# sDMA register map
Vendor: Texas Instruments
Peripheral module from a debugger description file (folder omap4460).
Registers are 32-bit, read-write, reset values left out (the file's numbers can be read two ways) unless marked. A register's access mark holds for its fields unless they carry their own. Offsets are as the file gives them; lines under a group give offsets from that group; [hi:lo] are bit positions; {n}, {i} and the like mark numbered series; 'fields as' and 'values as' point back to an identical list; <NAME> marks a mode.

## SDMA
0x00 DMA4_REVISION ro — This register contains the DMA revision code
  [31:0] REVISION — Reserved, Write 0's for future compatibility. Read returns 0
{0x8+4i} DMA4_IRQSTATUS_Lj_{i} (i=0..3) — The interrupt status register regroups all the status of the DMA4 channels that can generate an interrupt over line Lj.
  [31:0] CH_31_0_Lj — Channel 31 Interrupt on Lj: When an interrupt is seen on the line Lj the status of a interrupting channel i is read in the bit field i.
    0=CH_31_0_Lj_0_r (Channel Interrupt Lj false); 0=CH_31_0_Lj_0_w (Channel Interrupt Lj status bit unchanged); 1=CH_31_0_Lj_1_w (Channel Interrupt Lj status bit is reset); 1=CH_31_0_Lj_1_r (Channel Interrupt Lj true (pending))
{0x18+4i} DMA4_IRQENABLE_Lj_{i} (i=0..3) — The interrupt enable register allows to mask/unmask the module internal sources of interrupt, on line Lj
  [31:0] CH_31_0_Lj_EN — Channel Interrupt on Lj mask/unmask : to Mask/Unmask a channel i interrupt on Lj the user writes 0/1 on the bit field i.
    0=Channel Interrupt Lj is masked; 1=Channel Interrupt Lj generates an interrupt when it occurs
0x28 DMA4_SYSSTATUS ro — The register provides status information about the module excluding the interrupt status information (see interrupt status register)
  [0] RESETDONE — Internal reset monitoring
    0=RESETDONE_0_r (Internal module reset is on-going); 1=RESETDONE_1_r (Reset completed)
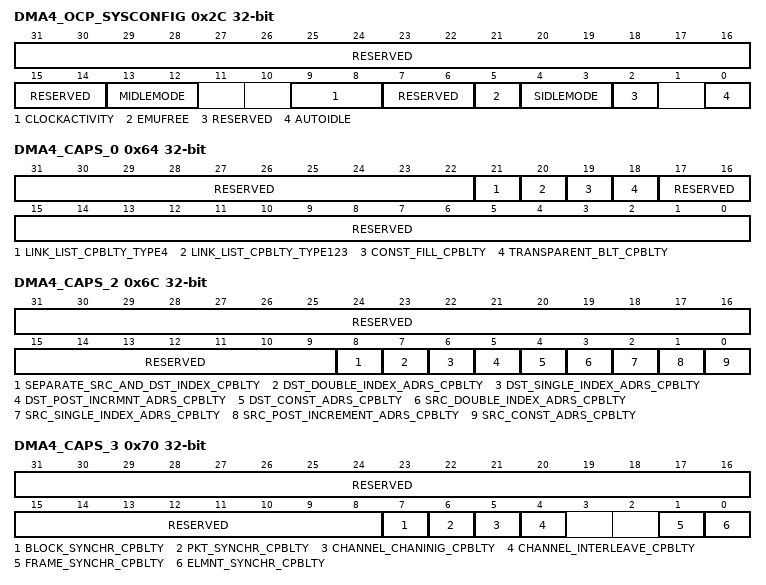
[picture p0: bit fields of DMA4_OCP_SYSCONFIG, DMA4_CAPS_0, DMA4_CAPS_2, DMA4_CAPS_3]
0x2C DMA4_OCP_SYSCONFIG access per field — DMA system configuration register
  [31:14] RESERVED rw — Write 0's for future compatibility, Reads return 0
  [13:12] MIDLEMODE rw — Read write power management, standby/wait control
    0=Force-standby: MStandby is asserted only when all the DMA channels are disabled; 1=No-Standby: MStandby is never asserted; 2=Smart-Standby: MStandby is asserted if at least one of the following two conditions is satisfied: 1. All the channels are disabled, OR 2. There is no non-synchronized channel enabled AND [if hardware synchronized channel is enabled, then no DMA request input is asserted and no requests are pending to be serviced].
  [9:8] CLOCKACTIVITY ro — Clocks activities during wake-up Bit 8: Interface clock 0x0: Interface clock can be switched-off Bit 9: Functional clock 0x0: Functional clock can be switched-off
  [7:6] RESERVED rw — Write 0's for future compatibility. Read returns 0
  [5] EMUFREE rw — Enable sensitivity to MSuspend
    0=DMA4 freezes its internal logic upon MSuspend assertion; 1=DMA4 ignores the MSuspend input
  [4:3] SIDLEMODE rw — Configuration port power management, Idle req/ack control
    0=Force-idle. An idle request is acknowledged unconditionally; 1=No-idle. An idle request is never acknowledged; 2=Smart-idle. Idle acknowledge is given by DMA4 if all of the conditions are true: 1. All the channels are disabled. 2. If hardware synchronized channel is enabled, then no DMA request input is asserted and no requests are pending to be serviced. 3. All transactions are completed on all the DMA ports. 4.No interrupts are pending to be serviced.; 3=Reserved. Do not use
  [2] RESERVED rw — Write 0's for future compatibility, Reads return 0
  [0] AUTOIDLE rw — Internal interface clock gating strategy
    0=Interface clock is free running; 1=Automatic interface clock gating strategy is applied, based on the interface activity
0x64 DMA4_CAPS_0 access per field — DMA Capabilities Register 0 LSW
  [31:22] RESERVED rw — Write 0's for future compatibility. Read returns 0
  [21] LINK_LIST_CPBLTY_TYPE4 ro — Link List capability for type4 descriptor capability
  [20] LINK_LIST_CPBLTY_TYPE123 ro — Link List capability for type123 descriptor capability
  [19] CONST_FILL_CPBLTY ro — Constant_Fill_Capability
    0=CONST_FILL_CPBLTY_0_r (No LCH supports constant fill copy); 1=CONST_FILL_CPBLTY_1_r (any LCH supports constant fill copy)
  [18] TRANSPARENT_BLT_CPBLTY ro — Transparent_BLT_Capability
    0=TRANSPARENT_BLT_CPBLTY_0_r (No LCH supports transparent BLT copy); 1=TRANSPARENT_BLT_CPBLTY_1_r (any LCH supports transparent BLT copy)
  [17:0] RESERVED rw — Write 0's for future compatibility. Read returns 0
0x6C DMA4_CAPS_2 ro — DMA Capabilities Register 2
  [31:9] RESERVED — Write 0's for future compatibility. Read returns 0
  [8] SEPARATE_SRC_AND_DST_INDEX_CPBLTY — Separate_source/destination_index_capability
    0=SEPARATE_SRC_AND_DST_INDEX_CPBLTY_0_r (Does not support separate src/dst index for 2D addressing); 1=SEPARATE_SRC_AND_DST_INDEX_CPBLTY_1_r (Supports separate src/dest index for 2D addressing)
  [7] DST_DOUBLE_INDEX_ADRS_CPBLTY — Destination_double_index_address_capability
    0=DST_DOUBLE_INDEX_ADRS_CPBLTY_0_r (Does not support double index address mode on the destination port); 1=DST_DOUBLE_INDEX_ADRS_CPBLTY_1_r (Supports double index address mode on the destination port)
  [6] DST_SINGLE_INDEX_ADRS_CPBLTY — Destination_single_index_address_capability
    0=DST_SINGLE_INDEX_ADRS_CPBLTY_0_r (Does not support single index address mode on the destination port); 1=DST_SINGLE_INDEX_ADRS_CPBLTY_1_r (Supports single index address mode on the destination port)
  [5] DST_POST_INCRMNT_ADRS_CPBLTY — Destination_post_increment_address_capability
    0=DST_POST_INCRMNT_ADRS_CPBLTY_0_r (Does not supports post-increment address mode in the destination port); 1=DST_POST_INCRMNT_ADRS_CPBLTY_1_r (Supports post-increment address mode in the destination port)
  [4] DST_CONST_ADRS_CPBLTY — Destination_constant_address_capability
    0=DST_CONST_ADRS_CPBLTY_0_r (Does not supports constant address mode in the destination port); 1=DST_CONST_ADRS_CPBLTY_1_r (Supports constant address mode in the destination port)
  [3] SRC_DOUBLE_INDEX_ADRS_CPBLTY — Source_double_index_address_capability
    0=SRC_DOUBLE_INDEX_ADRS_CPBLTY_0_r (Does not support double index address mode on the source port); 1=SRC_DOUBLE_INDEX_ADRS_CPBLTY_1_r (Supports double index address mode on the source port)
  [2] SRC_SINGLE_INDEX_ADRS_CPBLTY — Source_single_index_address_capability
    0=SRC_SINGLE_INDEX_ADRS_CPBLTY_0_r (Does not support single index address mode on the source port); 1=SRC_SINGLE_INDEX_ADRS_CPBLTY_1_r (Supports single index address mode in the source port)
  [1] SRC_POST_INCREMENT_ADRS_CPBLTY — Source_post_increment_address_capability
    0=SRC_POST_INCREMENT_ADRS_CPBLTY_0_r (Does not supports post-increment address mode in the source port); 1=SRC_POST_INCREMENT_ADRS_CPBLTY_1_r (Supports post-increment address mode in the source port)
  [0] SRC_CONST_ADRS_CPBLTY — Source_constant_address_capability
    0=SRC_CONST_ADRS_CPBLTY_0_r (Does not supports constant address mode in the source port); 1=SRC_CONST_ADRS_CPBLTY_1_r (Supports constant address mode in the source port)
0x70 DMA4_CAPS_3 ro — DMA Capabilities Register 3
  [31:8] RESERVED — Write 0's for future compatibility. Read returns 0
  [7] BLOCK_SYNCHR_CPBLTY — Block_synchronization_capability
    0=BLOCK_SYNCHR_CPBLTY_0_r (Does not support synchronization transfer on block boundary); 1=BLOCK_SYNCHR_CPBLTY_1_r (Supports synchronization transfer on block boundary)
  [6] PKT_SYNCHR_CPBLTY — Packet_synchronization_capability
    0=PKT_SYNCHR_CPBLTY_0_r (Does not support synchronization transfer on packet boundary); 1=PKT_SYNCHR_CPBLTY_1_r (Supports synchronization transfer on packet boundary)
  [5] CHANNEL_CHANINIG_CPBLTY — Channel_Chaninig_capability
    0=CHANNEL_CHANINIG_CPBLTY_0_r (Does not support Channel Chaninig capability); 1=CHANNEL_CHANINIG_CPBLTY_1_r (Supports Channel Chaninig capability)
  [4] CHANNEL_INTERLEAVE_CPBLTY — Channel_interleave_capability
    0=CHANNEL_INTERLEAVE_CPBLTY_0_r (Does not support Channel interleave capability); 1=CHANNEL_INTERLEAVE_CPBLTY_1_r (Supports Channel_interleave capability)
  [1] FRAME_SYNCHR_CPBLTY — Frame_synchronization_capability
    0=FRAME_SYNCHR_CPBLTY_0_r (Does not support synchronization transfer on Frame boundary); 1=FRAME_SYNCHR_CPBLTY_1_r (Supports synchronization transfer on Frame boundary)
  [0] ELMNT_SYNCHR_CPBLTY — Element_synchronization_capability
    0=ELMNT_SYNCHR_CPBLTY_0_r (Does not support synchronization transfer on Element boundary); 1=ELMNT_SYNCHR_CPBLTY_1_r (Supports synchronization transfer on Element boundary)
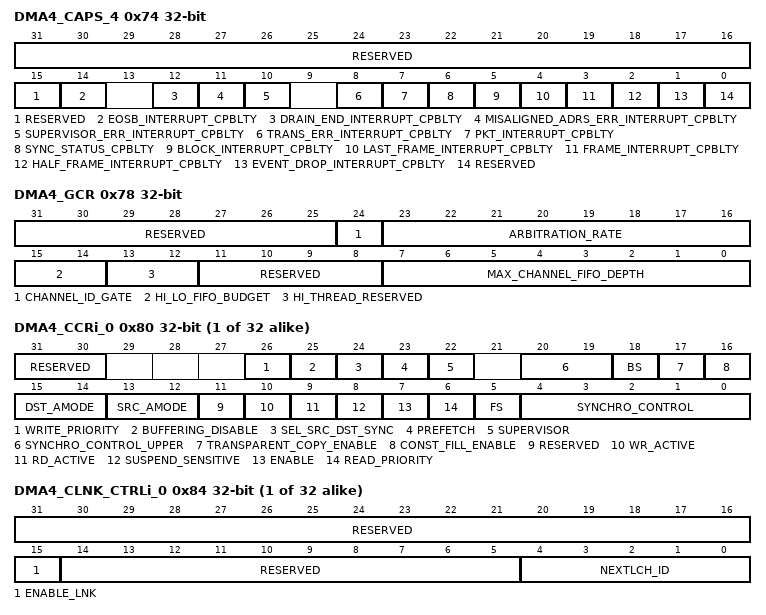
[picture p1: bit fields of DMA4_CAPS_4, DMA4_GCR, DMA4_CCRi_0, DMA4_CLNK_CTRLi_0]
0x74 DMA4_CAPS_4 access per field — DMA Capabilities Register 4
  [31:15] RESERVED rw — Write 0's for future compatibility. Read returns 0.
  [14] EOSB_INTERRUPT_CPBLTY ro — End of Super Block detection capability.
  [12] DRAIN_END_INTERRUPT_CPBLTY ro — Drain End detection capability.
  [11] MISALIGNED_ADRS_ERR_INTERRUPT_CPBLTY ro — Misaligned error detection capability.
  [10] SUPERVISOR_ERR_INTERRUPT_CPBLTY ro — Supervisor error detection capability.
  [8] TRANS_ERR_INTERRUPT_CPBLTY ro — Transaction error detection capability.
  [7] PKT_INTERRUPT_CPBLTY ro — End of Packet detection capability.
    0=PKT_INTERRUPT_CPBLTY_0_r (Does not support end of packet interrupt generation capability); 1=PKT_INTERRUPT_CPBLTY_1_r (Supports end of packet interrupt generation capability)
  [6] SYNC_STATUS_CPBLTY ro — Sync_status_capability
    0=SYNC_STATUS_CPBLTY_0_r (Does not support synchronized transfer status bit generation); 1=SYNC_STATUS_CPBLTY_1_r (Supports synchronized transfer status bit generation)
  [5] BLOCK_INTERRUPT_CPBLTY ro — End of block detection capability.
    0=BLOCK_INTERRUPT_CPBLTY_0_r (Does not support end of block interrupt generation capability); 1=BLOCK_INTERRUPT_CPBLTY_1_r (Supports end of block interrupt generation capability)
  [4] LAST_FRAME_INTERRUPT_CPBLTY ro — Start of last frame detection capability.
    0=LAST_FRAME_INTERRUPT_CPBLTY_0_r (Does not support last frame interrupt generation capability); 1=LAST_FRAME_INTERRUPT_CPBLTY_1_r (Supports last frame interrupt generation capability)
  [3] FRAME_INTERRUPT_CPBLTY ro — End of frame detection capability.
    0=FRAME_INTERRUPT_CPBLTY_0_r (Does not support end of frame interrupt generation capability); 1=FRAME_INTERRUPT_CPBLTY_1_r (Supports end of frame interrupt generation capability)
  [2] HALF_FRAME_INTERRUPT_CPBLTY ro — Detection capability of the half of frame end.
    0=HALF_FRAME_INTERRUPT_CPBLTY_0_r (Does not support half of frame interrupt generation capability); 1=HALF_FRAME_INTERRUPT_CPBLTY_1_r (Supports half of frame interrupt generation capability)
  [1] EVENT_DROP_INTERRUPT_CPBLTY ro — Request collision detection capability.
    0=EVENT_DROP_INTERRUPT_CPBLTY_0_r (Does not support event drop interrupt generation capability); 1=EVENT_DROP_INTERRUPT_CPBLTY_1_r (Supports event drop interrupt generation capability)
  [0] RESERVED rw — Write 0's for future compatibility. Read returns 0.
0x78 DMA4_GCR
  [31:25] RESERVED — Write 0's for future compatibility. Read returns 0.
  [24] CHANNEL_ID_GATE — Gates the Channel ID bus monitoring on both Read and Write ports 0x0: Gates the Channel ID qualifiers on both Read and Write Ports 0x1: Does not gate the Channel ID qualifiers on both Read and Write Ports
  [23:16] ARBITRATION_RATE — Arbitration switching rate between prioritized and regular channel queues
  [15:14] HI_LO_FIFO_BUDGET — Allow to have a separate Global FIFO budget for high and low priority channels. For Hi priority Channel: (Per_channel_Maximum FIFO depth + 1) x Number of active High priority Channel &lt;= High Budget FIFO For Low priority channel: (Per_channel_Maximum FIFO depth + 1) x Number of active Low priority Channel &lt;= Low Budget FIFO
    0=no fixed budget for neither higher nor lower priority channel; 1=75% of FIFO for low priority and 25% for high priority channels; 2=25% of FIFO for low priority and 75% for high priority channels; 3=50% of FIFO for low priority and 50% for high priority channels
  [13:12] HI_THREAD_RESERVED — Allow thread reservation for high priority channel on both read and write ports.
    0=No ThreadID is reserved on the Read Port for high priority channels. No ThreadID is reserved on the Write Port for high priority channels.; 1=Read Port ThreadID 0 is reserved for high priority channels. Write Port ThreadID 0 is reserved for high priority channels.; 2=Read port ThreadID 0 and ThreadID 1 are reserved for high priority channels. Write Port ThreadID 0 is reserved for high priority channels.; 3=Read PortThreadID 0, ThreadID 1 and ThreadID 2 are reserved for high priority channels. Write Port ThreadID 0 is reserved for high priority channels.
  [11:8] RESERVED — Write 0's for future compatibility. Read returns 0.
  [7:0] MAX_CHANNEL_FIFO_DEPTH — Maximum FIFO depth allocated to one logical channel. Maximum FIFO depth can not be 0x0. It should be at least 0x1 or greater. Note that If channel limit is less than destination burst size enough data will not be accumulated in the data FIFO and it will never be sent out on the WR port. The burst size should be less than the FIFO limit specified in this bit field.
{0x80+0x60*i} DMA4_CCRi_{i} access per field (i=0..31) — Channel Control Register
  [31:30] RESERVED rw — Write 0's for future compatibility. Read returns 0.
  [26] WRITE_PRIORITY rw — Channel priority on the Write side
    0=Channel has low priority on the write side during the arbitration process; 1=Channel has high priority on write sided during the arbitration process
  [25] BUFFERING_DISABLE rw — This bit allows to disable the default buffering functionality when transfer is source synchronized.
    0=Buffering is enabled across element/packet when source is synchronized to element, packet, frame or blocks; 1=Buffering is disabled across element/packet when source is synchronized to element, packet, frame or blocks
  [24] SEL_SRC_DST_SYNC rw — Specifies that element, packet, frame or block transfer (depending on CCR.bs and CCR.fs) is triggered by the source or the destination on the DMA request
    0=Transfer is triggered by the destination. If synch on packet the packet element number is specified in the CDFI register.; 1=Transfer is triggered by the source. If synchronized on packet the packet element number is specified in the CSFI register.
  [23] PREFETCH rw — Enables the prefetch mode
    0=Prefetch mode is disabled. When Sel_Src_Dst_Sync=1 transfers are buffered and pipelined between DMA requests.; 1=Prefetch mode is enabled. Prefetch mode is active only when destination is synchronized. It is software user responsibility not to have at the same time Prefetch=1 when Sel_Src_Dst_Sync=1. This mode is not supported.
  [22] SUPERVISOR rw — Enables the supervisor mode
    0=Supervisor mode is disabled; 1=Supervisor mode is enabled
  [20:19] SYNCHRO_CONTROL_UPPER rw — Channel Synchronization control upper (used in conjunction with the 5 bits of synchro channelDMA4_CCRi[4:0]) Used in conjunction, as 2 MSB, with the 5 bits of the synchro channel bit field.
  [18] BS rw — Block synchronization This bit used in conjunction with the fs to see how the DMA request is serviced in a synchronized transfer.
  [17] TRANSPARENT_COPY_ENABLE rw
    0=Transparent copy mode is disabled; 1=Transparent copy mode is enabled
  [16] CONST_FILL_ENABLE rw — Constant fill enable
    0=Constant fill mode is disabled; 1=Constant fill mode is enabled
  [15:14] DST_AMODE rw — Selects the addressing mode on the Write Port of a channel.
    0=Constant address mode; 1=Post-incremented address mode; 2=Single index address mode; 3=Double index address mode
  [13:12] SRC_AMODE rw — Selects the addressing mode on the Read Port of a channel.
    values as DST_AMODE
  [11] RESERVED rw — Write 0s for future compatibility. Read returns 0.
  [10] WR_ACTIVE ro — Indicates if the channel write context is active or not
    0=WR_ACTIVE_0_r (Channel is not active on the write port.); 1=WR_ACTIVE_1_r (Channel is currently active on the write port.)
  [9] RD_ACTIVE ro — Indicates if the channel read context is active or not
    0=RD_ACTIVE_0_r (Channel is not active on the read port.); 1=RD_ACTIVE_1_r (Channel is currently active on the read port.)
  [8] SUSPEND_SENSITIVE rw — Logical channel suspend enable bit
    0=The channel ignores the MSuspend even if EMUFree is set to 0; 1=If EMUFree is set to 0 and MSuspend comes in then all current OCP services (single transaction or burst transaction as specified in the corresponding CSDP register) have to be completed before stopping processing any more transactions
  [7] ENABLE rw — Logical channel enable. It is SW responsibility to clear the CSR register and the IRQSTATUS bit for the different interrupt lines before enabling the channel.
    0=The logical channel is disabled; 1=The logical channel is enabled
  [6] READ_PRIORITY rw — Channel priority on the read side
    0=Channel has low priority on the read side during the arbitration process; 1=Channel has high priority on read sided during the arbitration process
  [5] FS rw — Frame synchronization This bit used in conjunction with the BS to see how the DMA request is serviced in a synchronized transfer FS = 0 and BS = 0: An element is transferred once a DMA request is made. FS = 0 and BS = 1: An entire block is transferred once a DMA request is made. FS = 1 and BS = 0: An entire frame is transferred once a DMA request is made. FS = 1 and BS = 1: A packet is transferred once a DMA request is made. All these different transfers can be interleaved on the port with other DMA requests.
  [4:0] SYNCHRO_CONTROL rw — Channel synchronization control This bit field used in conjunction with the second_level_ synchro_control_upper (as 2 MSB) 0000000 : Is reserved for non synchronized LCH transfer xxxxxxx (from 1 to 127)There are 127 possible DMA request to assign to any LCH. The channel synchronization control registers are 1-based. For example, to enable the S_DMA_1 request, DMA4_CCR[4:0] SYNCHRO_CONTROL must be set to 0x2 (DMA request number + 1).
{0x84+0x60*i} DMA4_CLNK_CTRLi_{i} (i=0..31) — Channel Link Control Register
  [31:16] RESERVED — Write 0's for future compatibility. Read returns 0.
  [15] ENABLE_LNK — Enables or disable the channel linking.
    0=Channel linking mode is disabled When set on the fly to 0 the current channel will complete the transfer and stops the chain linking; 1=Channel linking mode is enabled. The logical channel defined in the NextLCH_ID is enabled at the end of the current transfer
  [14:5] RESERVED — Write 0's for future compatibility. Read returns 0.
  [4:0] NEXTLCH_ID — Defines the NextLCh_ID, which is used to build logical channel chaining queue.
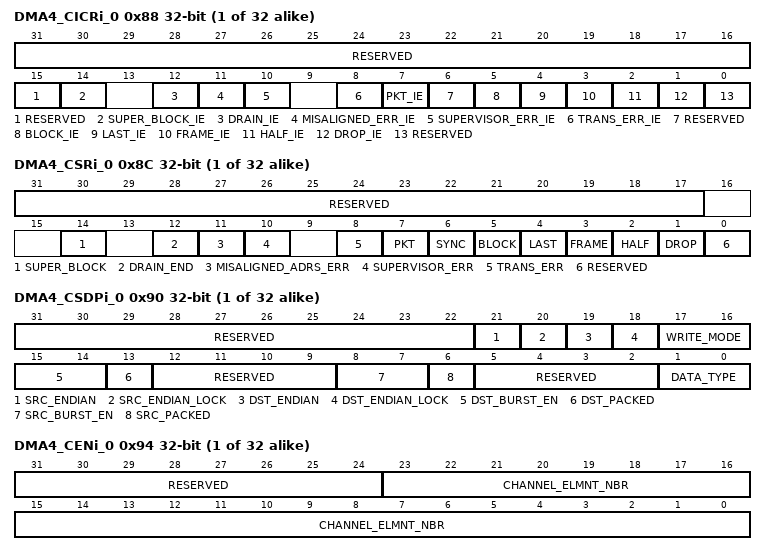
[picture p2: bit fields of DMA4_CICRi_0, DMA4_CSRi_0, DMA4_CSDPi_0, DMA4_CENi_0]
{0x88+0x60*i} DMA4_CICRi_{i} (i=0..31) — Channel Interrupt Control Register
  [31:15] RESERVED — Write 0's for future compatibility. Read returns 0.
  [14] SUPER_BLOCK_IE — Enables the end of super block interrupt
  [12] DRAIN_IE — Enables the end of draining interrupt
  [11] MISALIGNED_ERR_IE — Enables the address misaligned error event interrupt
    0=Disables the misaligned address error event interrupt; 1=Enables the misaligned address error event interrupt
  [10] SUPERVISOR_ERR_IE — Enables the supervisor transaction error event interrupt
    0=Disables the supervisor transaction error event interrupt; 1=Enables the supervisor transaction error event interrupt
  [8] TRANS_ERR_IE — Enables the transaction error event interrupt
    0=Disables the transaction error event interrupt; 1=Enables the transaction error event interrupt
  [7] PKT_IE — Enables the end of Packet interrupt
    0=Disables the end of Packet transfer interrupt; 1=Enables the end of Packet transfer interrupt
  [6] RESERVED — Write 0's for future compatibility. Read returns 0.
  [5] BLOCK_IE — Enables the end of block interrupt
    0=Disables the end of block interrupt; 1=Disables the end of block interrupt
  [4] LAST_IE — Last frame interrupt enable (start of last frame)
    0=Disables the last frame interrupt; 1=Enables the last frame interrupt
  [3] FRAME_IE — Frame interrupt enable (end of frame)
    0=Disables the end of frame interrupt; 1=Enables the end of frame interrupt
  [2] HALF_IE — Enables or disables the half frame interrupt.
    0=Disables the half frame interrupt; 1=Enables the half frame interrupt
  [1] DROP_IE — Synchronization event drop interrupt enable (request collision)
    0=Disables the event drop interrupt; 1=Enables the event drop interrupt
  [0] RESERVED — Write 0's for future compatibility. Read returns 0.
{0x8C+0x60*i} DMA4_CSRi_{i} (i=0..31) — Channel Status Register
  [31:17] RESERVED — Write 0's for future compatibility. Read returns 0.
  [14] SUPER_BLOCK — End of Super block event
  [12] DRAIN_END — End of channel draining
  [11] MISALIGNED_ADRS_ERR — Misaligned address error event
    0=MISALIGNED_ADRS_ERR_0_r (No address error); 0=MISALIGNED_ADRS_ERR_0_w (Status bit unchanged); 1=MISALIGNED_ADRS_ERR_1_w (Status bit is reset); 1=MISALIGNED_ADRS_ERR_1_r (An address error has been occurred)
  [10] SUPERVISOR_ERR — Supervisor transaction error event
    0=SUPERVISOR_ERR_0_r (No supervisor transaction error); 0=SUPERVISOR_ERR_0_w (Status bit unchanged); 1=SUPERVISOR_ERR_1_w (Status bit is reset); 1=SUPERVISOR_ERR_1_r (A supervisor transaction error has been occurred)
  [8] TRANS_ERR — Transaction error event
    0=TRANS_ERR_0_r (No transaction error); 0=TRANS_ERR_0_w (Status bit unchanged); 1=TRANS_ERR_1_w (Status bit is reset); 1=TRANS_ERR_1_r (A transaction error has been occurred)
  [7] PKT — End of Packet transfer
    0=PKT_0_r (The current packet transfer has not been finished); 0=PKT_0_w (Status bit unchanged); 1=PKT_1_w (Status bit is reset); 1=PKT_1_r (The current packet has been transferred)
  [6] SYNC — Synchronization status of a channel.
    0=SYNC_0_r (Logical channel is not scheduled or servicing a non synchronized DMA request.); 0=SYNC_0_w (Status bit unchanged); 1=SYNC_1_w (Status bit is reset); 1=SYNC_1_r (Logical channel is servicing a synchronized DMA request)
  [5] BLOCK — End of block event
    0=BLOCK_0_r (The current block transfer has not been finished); 0=BLOCK_0_w (Status bit unchanged); 1=BLOCK_1_w (Status bit is reset); 1=BLOCK_1_r (The current block has been transferred)
  [4] LAST — Last frame (start of last frame)
    0=LAST_0_r (The start of the last frame to transfer is not reached); 0=LAST_0_w (Status bit unchanged); 1=LAST_1_w (Status bit is reset); 1=LAST_1_r (The start of the last frame to transfer is reached)
  [3] FRAME — End of frame event
    0=FRAME_0_r (The end of current transferred frame is not reached); 0=FRAME_0_w (Status bit unchanged); 1=FRAME_1_w (Status bit is reset); 1=FRAME_1_r (The end of current transferred frame is reached)
  [2] HALF — Half of frame event.
    0=HALF_0_r (The half of current transferred frame is not reached); 0=HALF_0_w (Status bit unchanged); 1=HALF_1_w (Status bit is reset); 1=HALF_1_r (The half of current transferred frame is reached)
  [1] DROP — Synchronization event drop occured during the transfer
    0=DROP_0_r (No synchronization collision); 0=DROP_0_w (Status bit unchanged); 1=DROP_1_w (Status bit is reset); 1=DROP_1_r (A synchronization collision has been occurred)
  [0] RESERVED — Write 0's for future compatibility. Read returns 0.
{0x90+0x60*i} DMA4_CSDPi_{i} (i=0..31) — Channel Source Destination Parameters
  [31:22] RESERVED — Write 0's for future compatibility. Read returns 0.
  [21] SRC_ENDIAN — Channel source endianness control
    0=Source has Little Endian type; 1=Source has Big Endian type
  [20] SRC_ENDIAN_LOCK — Endianness Lock
    0=Endianness adapt; 1=Endianness lock
  [19] DST_ENDIAN — Channel Destination endianness control
    0=Destination has Little Endian type; 1=Destination has Big Endian type
  [18] DST_ENDIAN_LOCK — Endianness Lock
    0=Endianness adapt; 1=Endianness lock
  [17:16] WRITE_MODE — Used to enable writing mode without posting or with posting
    0=Write None Posted (WRNP); 1=Write (Posted); 2=All transaction are mapped on the Write command as posted except for the last transaction in the transfer mapped on a Write None Posted; 3=Undefined
  [15:14] DST_BURST_EN — Used to enable bursting on the Write Port. Smaller burst size than the programmed burst size is also allowed
    0=single access; 1=16 bytes or 4x32-bit / 2x64-bit burst access; 2=32 bytes or 8x32-bit / 4x64-bit burst access; 3=64 bytes or 16x32-bit / 8x64-bit burst access
  [13] DST_PACKED — Destination receives packed data.
    0=The destination target is non packed; 1=The destination target is packed
  [12:9] RESERVED — Write the reset value. Read returns reset value
  [8:7] SRC_BURST_EN — Used to enable bursting on the Read Port. Smaller burst size than the programmed burst size is also allowed
    values as DST_BURST_EN
  [6] SRC_PACKED — Source provides packed data.
    0=The source target is non packed; 1=The source target is packed
  [5:2] RESERVED — Write the reset value. Read returns reset value
  [1:0] DATA_TYPE — Defines the type of the data moved in the channel.
    0=8 bits scalar; 1=16 bits scalar; 2=32 bits scalar
{0x94+0x60*i} DMA4_CENi_{i} (i=0..31) — Channel Element Number
  [31:24] RESERVED — Write 0's for future compatibility. Read returns 0.
  [23:0] CHANNEL_ELMNT_NBR — Number of elements within a frame (unsigned) to transfer
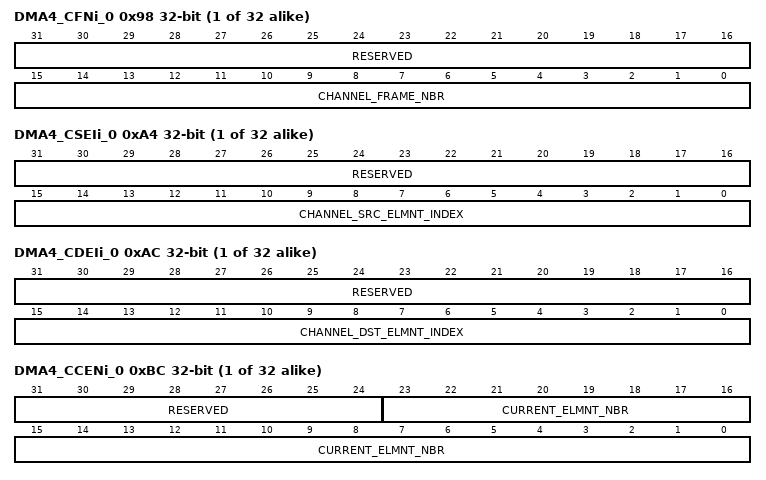
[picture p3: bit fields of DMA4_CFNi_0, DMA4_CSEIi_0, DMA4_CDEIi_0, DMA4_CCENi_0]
{0x98+0x60*i} DMA4_CFNi_{i} (i=0..31) — Channel Frame Number
  [31:16] RESERVED — Write 0's for future compatibility. Read returns 0.
  [15:0] CHANNEL_FRAME_NBR — Number of frames within the block to be transferred (unsigned)
{0x9C+0x60*i} DMA4_CSSAi_{i} (i=0..31) — Channel Source Start Address
  [31:0] SRC_START_ADRS — 32 bits of the source start address
{0xA0+0x60*i} DMA4_CDSAi_{i} (i=0..31) — Channel Destination Start Address
  [31:0] DST_START_ADRS — 32 bits of the destination start address
{0xA4+0x60*i} DMA4_CSEIi_{i} (i=0..31) — Channel Source Element Index (Signed)
  [31:16] RESERVED — Write 0's for future compatibility. Read returns 0.
  [15:0] CHANNEL_SRC_ELMNT_INDEX — Channel source element index
{0xA8+0x60*i} DMA4_CSFIi_{i} (i=0..31) — Channel Source Frame Index (Signed) or 16-bit Packet size
  [31:0] CH_SRC_FRM_INDEX_OR_16BIT_PKT_ELNT_NBR — Channel source frame index value if source address is in double index mode. Or if fs=bs=1 and DMA_CCR[SEL_SRC_DST_SYNC] = 1; the bit field [15:0] gives the number of element in packet. The field [31:16] is unused for the packet size.
{0xAC+0x60*i} DMA4_CDEIi_{i} (i=0..31) — Channel Destination Element Index (Signed)
  [31:16] RESERVED — Write 0's for future compatibility. Read returns 0.
  [15:0] CHANNEL_DST_ELMNT_INDEX — Channel destination element index
{0xB0+0x60*i} DMA4_CDFIi_{i} (i=0..31) — Channel Destination Frame Index (Signed) or 16-bit Packet size
  [31:0] CH_DST_FRM_IDX_OR_16BIT_PKT_ELNT_NBR — Channel destination frame index value if destination address is in double index mode. Or if fs=bs=1 and DMA_CCR[SEL_SRC_DST_SYNC]=0; the bit field [15:0] gives the number of element in packet. The field [31:16] is unused for the packet size..
{0xB4+0x60*i} DMA4_CSACi_{i} ro (i=0..31) — Channel Source Address Value. User has to access this register only in 32-bit access. If accessed in 8-bit or 16bit data may be corrupted.
  [31:0] SRC_ELMNT_ADRS — Current source address counter value
{0xB8+0x60*i} DMA4_CDACi_{i} (i=0..31) — Channel Destination Address Value. User has to access this register only in 32-bit access. If accessed in 8-bit or 16bit data may be corrupted.
  [31:0] DST_ELMNT_ADRS — Current destination address counter value
{0xBC+0x60*i} DMA4_CCENi_{i} (i=0..31) — Channel Current Transferred Element Number in the current frame. User has to access this register only in 32-bit access. If accessed in 8-bit or 16bit data may be corrupted.
  [31:24] RESERVED — Write 0's for future compatibility. Read returns 0.
  [23:0] CURRENT_ELMNT_NBR — Channel current transferred element number in the current frame
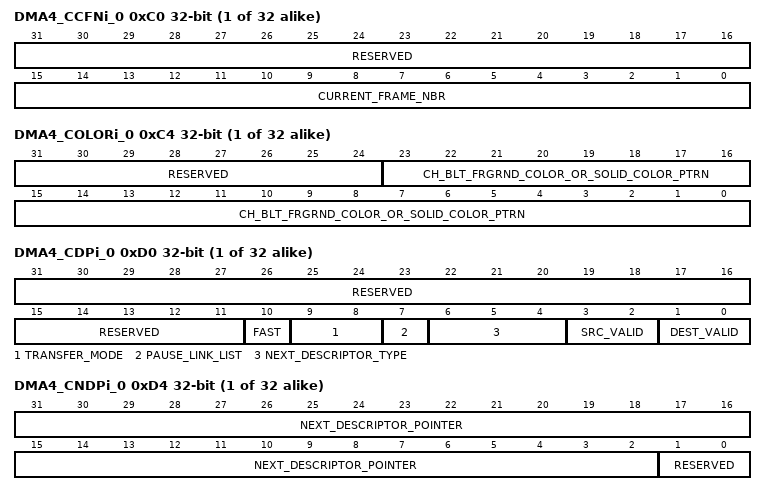
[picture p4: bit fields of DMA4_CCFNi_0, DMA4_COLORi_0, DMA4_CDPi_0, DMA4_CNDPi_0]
{0xC0+0x60*i} DMA4_CCFNi_{i} (i=0..31) — Channel Current Transferred Frame Number in the current transfer. User has to access this register only in 32-bit access. If accessed in 8-bit or 16bit data may be corrupted.
  [31:16] RESERVED — Write 0's for future compatibility. Read returns 0.
  [15:0] CURRENT_FRAME_NBR — Channel current transferred frame number in the current transfer
{0xC4+0x60*i} DMA4_COLORi_{i} (i=0..31) — Channel DMA COLOR KEY /SOLID COLOR
  [31:24] RESERVED — Write 0's for future compatibility. Read returns 0.
  [23:0] CH_BLT_FRGRND_COLOR_OR_SOLID_COLOR_PTRN — Color key or solid color pattern: The pattern is replicated according to the data type. If the data-type is 8-bit the pattern is replicated 4 times to fill the register in order to enhance processing when data is packed at the graphic module input. The same reasoning for 16-bit data-type.
{0xD0+0x60*i} DMA4_CDPi_{i} (i=0..31) — This register controls the various parameters of the link list mechanism
  [31:11] RESERVED — Write 0's for future compatibility, Reads return 0
  [10] FAST — Sets the fast-start mode for linked list descriptor types 1, 2 and 3
    0=No fast-start mode; 1=Fast-start mode is enabled
  [9:8] TRANSFER_MODE — Enable linked-list transfer mode
    0=Normal transfer mode is used; 1=Linked-list channel mode for type 1, 2, or 3 descriptor is used; 2=Undefined; 3=Undefined
  [7] PAUSE_LINK_LIST — Suspend the linked-list transfer at completion of the current block transfer.
    0=Linked list is active; 1=Linked list is suspended at the boundary of next descriptor loading
  [6:4] NEXT_DESCRIPTOR_TYPE
    0=Undefined; 1=Next descriptor is of type 1; 2=Next descriptor is of type 2; 3=Next descriptor is of type 3; {v}=Undefined (v=4..7)
  [3:2] SRC_VALID — Source address valid
    0=The source address is not present in the next descriptor and continuous incrementing is enabled; 1=The source address must be reloaded in the next descriptor transfer; 2=The source start address is not present in the next descriptor. But will reload the one from configuration memory which belongs to the previous descriptor.; 3=Undefined addressing mode
  [1:0] DEST_VALID — Destination address valid
    0=The destination address is not present in the next descriptor and continuous incrementing is enabled; 1=The destination address must be reloaded in the next descriptor transfer; 2=The destination start address is not present in the next descriptor. But will reload the one from configuration memory which belongs to the previous descriptor.; 3=Undefined addressing mode
{0xD4+0x60*i} DMA4_CNDPi_{i} (i=0..31) — This register contains the Next descriptor Address Pointer for the link list Mechanism
  [31:2] NEXT_DESCRIPTOR_POINTER — This register contains the Next descriptor Address Pointer for the link list Mechanism
  [1:0] RESERVED — Write 0's for future compatibility, Reads return 0
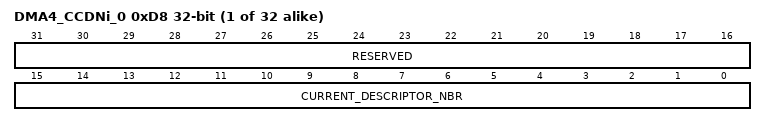
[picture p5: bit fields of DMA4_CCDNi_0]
{0xD8+0x60*i} DMA4_CCDNi_{i} (i=0..31)
  [31:16] RESERVED — Write 0's for future compatibility, Reads return 0
  [15:0] CURRENT_DESCRIPTOR_NBR — This register when read contains the current active descriptor number in the link list. This register is Read/write to allow user initialization.
